# MKW36Z4 register map
Vendor: NXP Semiconductors; Series: Kinetis_W; File version: 1.6
CPU: CM0PLUS r0p0, little endian, no MPU, no FPU, VTOR, 2 interrupt priority bits
Registers are 16-bit, read-write, no defined reset value unless marked. A register's access mark holds for its fields unless they carry their own. Offsets are from the block's base; [hi:lo] are bit positions; {n}, {i} and the like mark numbered series; 'fields as' and 'values as' point back to an identical list.

## RFSYS — System register file
Base 0x40041000; register names take the prefix RFSYS_
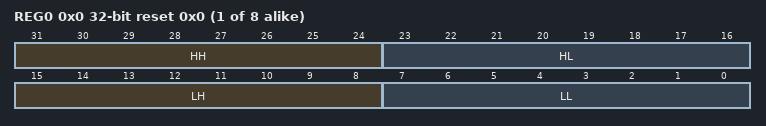
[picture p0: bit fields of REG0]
{0x0+4i} REG{i} (i=0..7) 32-bit reset 0x0 — Register file register
  [31:24] HH — High higher byte
  [23:16] HL — High lower byte
  [15:8] LH — Low higher byte
  [7:0] LL — Low lower byte

## PORTA — PORT
Base 0x40049000
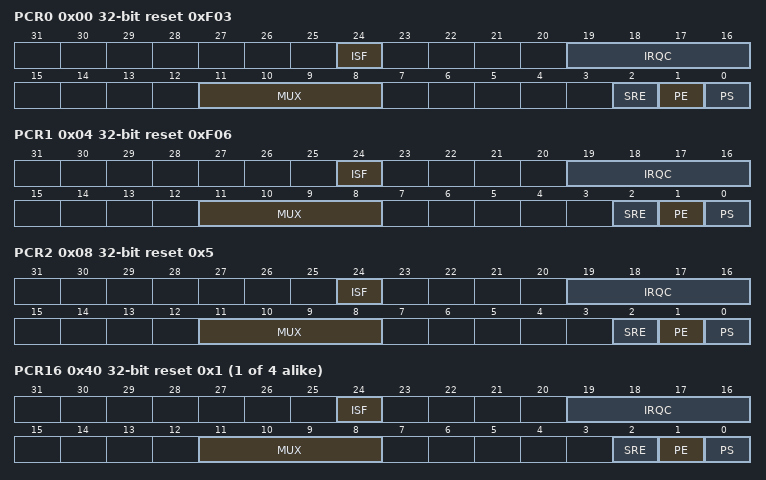
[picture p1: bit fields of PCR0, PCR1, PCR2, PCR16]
0x00 PCR0 32-bit reset 0xF03 — Pin Control Register 0
  [24] ISF — Interrupt Status Flag
    0=Configured interrupt is not detected
  [19:16] IRQC — Interrupt Configuration
    0=Interrupt Status Flag (ISF) is disabled; 1=ISF flag and DMA request on rising edge; 2=ISF flag and DMA request on falling edge; 3=ISF flag and DMA request on either edge; 8=ISF flag and Interrupt when logic 0; 9=ISF flag and Interrupt on rising-edge; 10=ISF flag and Interrupt on falling-edge; 11=ISF flag and Interrupt on either edge; 12=ISF flag and Interrupt when logic 1
  [11:8] MUX — Pin Mux Control
    0=Pin disabled (Alternative 0) (analog); 1=Alternative 1 (GPIO); {v}=Alternative {v} (chip-specific) (v=2..15)
  [2] SRE — Slew Rate Enable
    0=Fast slew rate is configured on the corresponding pin, if the pin is configured as a digital output; 1=Slow slew rate is configured on the corresponding pin, if the pin is configured as a digital output
  [1] PE — Pull Enable
  [0] PS — Pull Select
    0=Internal pulldown resistor is enabled on the corresponding pin, if the corresponding PE field is set; 1=Internal pullup resistor is enabled on the corresponding pin, if the corresponding PE field is set
0x04 PCR1 32-bit reset 0xF06 — Pin Control Register 1
  fields as PCR0
0x08 PCR2 32-bit reset 0x5 — Pin Control Register 2
  fields as PCR0
{0x0+4i} PCR{i} 32-bit reset 0x1 (i=16..19) — Pin Control Register {i}
  fields as PCR0
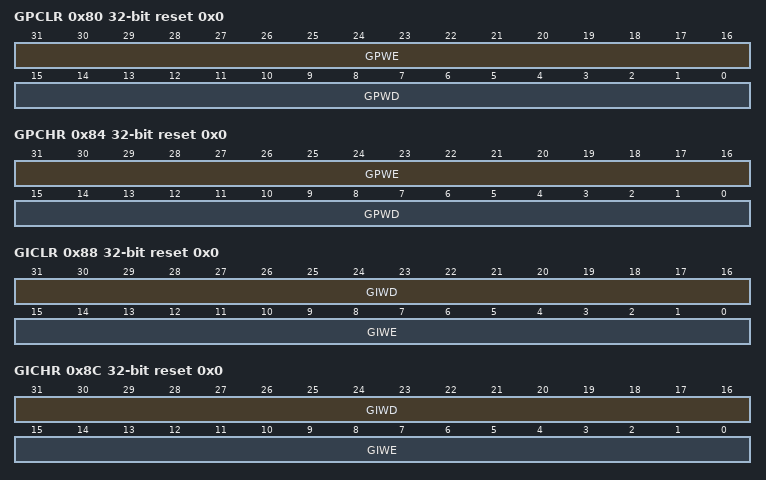
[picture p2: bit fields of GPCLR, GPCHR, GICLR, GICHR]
0x80 GPCLR 32-bit wo reset 0x0 — Global Pin Control Low Register
  [31:16] GPWE — Global Pin Write Enable
  [15:0] GPWD — Global Pin Write Data
0x84 GPCHR 32-bit wo reset 0x0 — Global Pin Control High Register
  fields as GPCLR
0x88 GICLR 32-bit wo reset 0x0 — Global Interrupt Control Low Register
  [31:16] GIWD — Global Interrupt Write Data
  [15:0] GIWE — Global Interrupt Write Enable
0x8C GICHR 32-bit wo reset 0x0 — Global Interrupt Control High Register
  fields as GICLR
0xA0 ISFR 32-bit reset 0x0 — Interrupt Status Flag Register
  [31:0] ISF — Interrupt Status Flag

## PORTB — PORT
Base 0x4004A000
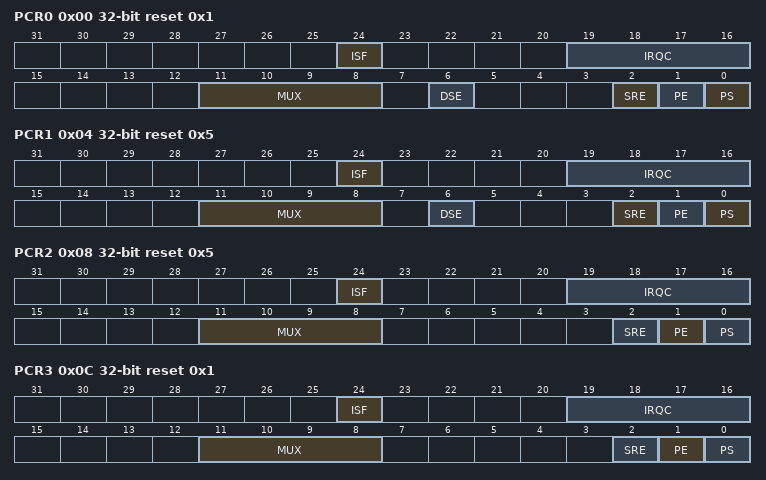
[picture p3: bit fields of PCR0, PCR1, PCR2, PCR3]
0x00 PCR0 32-bit reset 0x1 — Pin Control Register 0
  [24] ISF — Interrupt Status Flag
    0=Configured interrupt is not detected
  [19:16] IRQC — Interrupt Configuration
    0=Interrupt Status Flag (ISF) is disabled; 1=ISF flag and DMA request on rising edge; 2=ISF flag and DMA request on falling edge; 3=ISF flag and DMA request on either edge; 8=ISF flag and Interrupt when logic 0; 9=ISF flag and Interrupt on rising-edge; 10=ISF flag and Interrupt on falling-edge; 11=ISF flag and Interrupt on either edge; 12=ISF flag and Interrupt when logic 1
  [11:8] MUX — Pin Mux Control
    0=Pin disabled (Alternative 0) (analog); 1=Alternative 1 (GPIO); {v}=Alternative {v} (chip-specific) (v=2..15)
  [6] DSE — Drive Strength Enable
    0=Low drive strength is configured on the corresponding pin, if pin is configured as a digital output; 1=High drive strength is configured on the corresponding pin, if pin is configured as a digital output
  [2] SRE — Slew Rate Enable
    0=Fast slew rate is configured on the corresponding pin, if the pin is configured as a digital output; 1=Slow slew rate is configured on the corresponding pin, if the pin is configured as a digital output
  [1] PE — Pull Enable
  [0] PS — Pull Select
    0=Internal pulldown resistor is enabled on the corresponding pin, if the corresponding PE field is set; 1=Internal pullup resistor is enabled on the corresponding pin, if the corresponding PE field is set
0x04 PCR1 32-bit reset 0x5 — Pin Control Register 1
  fields as PCR0
0x08 PCR2 32-bit reset 0x5 — Pin Control Register 2
  [24] ISF — Interrupt Status Flag
    0=Configured interrupt is not detected
  [19:16] IRQC — Interrupt Configuration
    values as PCR0.IRQC
  [11:8] MUX — Pin Mux Control
    values as PCR0.MUX
  [2] SRE — Slew Rate Enable
    values as PCR0.SRE
  [1] PE — Pull Enable
  [0] PS — Pull Select
    values as PCR0.PS
0x0C PCR3 32-bit reset 0x1 — Pin Control Register 3
  fields as PCR2
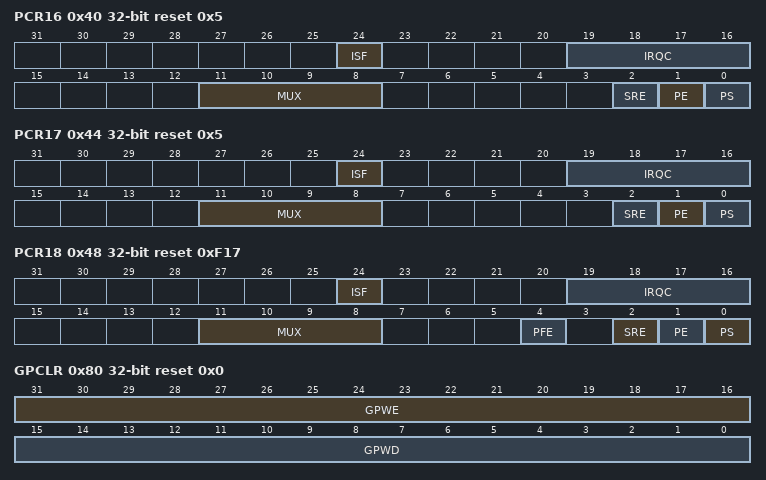
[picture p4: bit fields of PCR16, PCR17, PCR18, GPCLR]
0x40 PCR16 32-bit reset 0x5 — Pin Control Register 16
  fields as PCR2
0x44 PCR17 32-bit reset 0x5 — Pin Control Register 17
  fields as PCR2
0x48 PCR18 32-bit reset 0xF17 — Pin Control Register 18
  [24] ISF — Interrupt Status Flag
    0=Configured interrupt is not detected
  [19:16] IRQC — Interrupt Configuration
    values as PCR0.IRQC
  [11:8] MUX — Pin Mux Control
    values as PCR0.MUX
  [4] PFE — Passive Filter Enable
    0=Passive input filter is disabled on the corresponding pin; 1=Passive input filter is enabled on the corresponding pin, if the pin is configured as a digital input. Refer to the device data sheet for filter characteristics.
  [2] SRE — Slew Rate Enable
    values as PCR0.SRE
  [1] PE — Pull Enable
  [0] PS — Pull Select
    values as PCR0.PS
0x80 GPCLR 32-bit wo reset 0x0 — Global Pin Control Low Register
  [31:16] GPWE — Global Pin Write Enable
  [15:0] GPWD — Global Pin Write Data
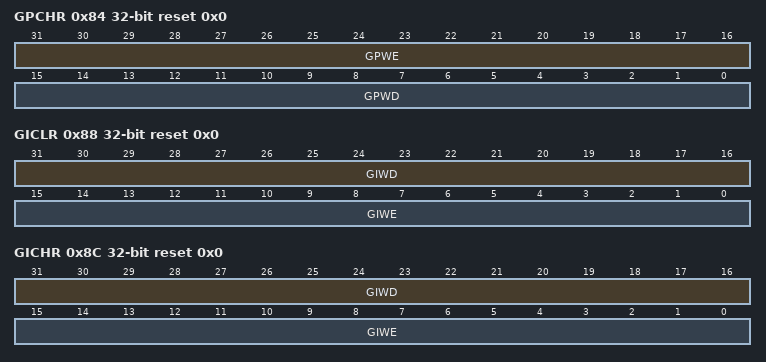
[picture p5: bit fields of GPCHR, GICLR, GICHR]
0x84 GPCHR 32-bit wo reset 0x0 — Global Pin Control High Register
  fields as GPCLR
0x88 GICLR 32-bit wo reset 0x0 — Global Interrupt Control Low Register
  [31:16] GIWD — Global Interrupt Write Data
  [15:0] GIWE — Global Interrupt Write Enable
0x8C GICHR 32-bit wo reset 0x0 — Global Interrupt Control High Register
  fields as GICLR
0xA0 ISFR 32-bit reset 0x0 — Interrupt Status Flag Register
  [31:0] ISF — Interrupt Status Flag
